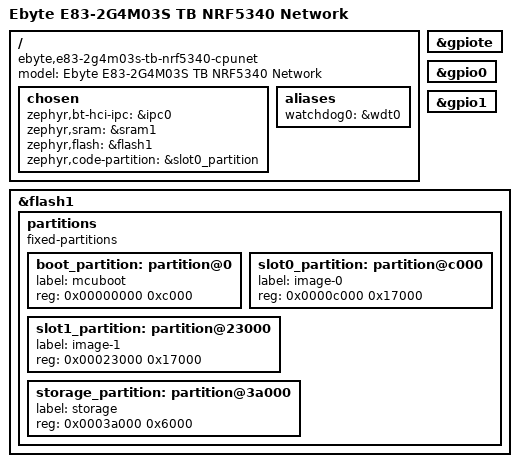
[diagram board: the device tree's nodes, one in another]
/*
 * Copyright (c) 2020 Nordic Semiconductor ASA
 *
 * SPDX-License-Identifier: Apache-2.0
 *
 * E83-2G4M03S Test Board (10414-PCB-V1.2) — Network core
 * BLE-only SW Split LL controller. No UART, I2C, or SPI on net core.
 */

/dts-v1/;
#include <nordic/nrf5340_cpunet_qkaa.dtsi>
#include "e83_2g4m03s_tb_common.dtsi"
#include "e83_2g4m03s_tb_nrf5340_cpunet-pinctrl.dtsi"

/ {
	model = "Ebyte E83-2G4M03S TB NRF5340 Network";
	compatible = "ebyte,e83-2g4m03s-tb-nrf5340-cpunet";

	chosen {
		zephyr,bt-hci-ipc = &ipc0;
		zephyr,sram = &sram1;
		zephyr,flash = &flash1;
		zephyr,code-partition = &slot0_partition;
	};

	aliases {
		watchdog0 = &wdt0;
	};
};

&gpiote {
	status = "okay";
};

&gpio0 {
	status = "okay";
};

&gpio1 {
	status = "okay";
};

&flash1 {
	partitions {
		compatible = "fixed-partitions";
		#address-cells = <1>;
		#size-cells = <1>;

		boot_partition: partition@0 {
			label = "mcuboot";
			reg = <0x00000000 0xc000>;
		};

		slot0_partition: partition@c000 {
			label = "image-0";
			reg = <0x0000c000 0x17000>;
		};

		slot1_partition: partition@23000 {
			label = "image-1";
			reg = <0x00023000 0x17000>;
		};

		storage_partition: partition@3a000 {
			label = "storage";
			reg = <0x0003a000 0x6000>;
		};
	};
};

/* Include default shared RAM configuration file */
#include <nordic/nrf5340_shared_sram_partition.dtsi>
